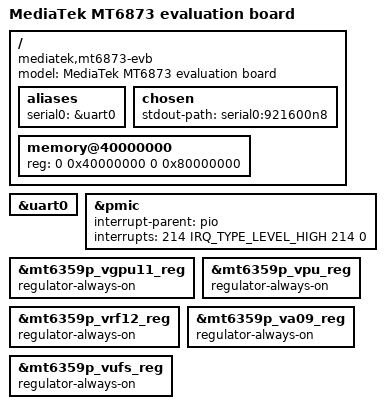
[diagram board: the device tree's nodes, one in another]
// SPDX-License-Identifier: (GPL-2.0 OR MIT)
/*
 * Copyright (C) 2020 MediaTek Inc.
 * Author: Seiya Wang <seiya.wang@mediatek.com>
 */
/dts-v1/;
#include "mt6873.dtsi"
#include "mt6359p.dtsi"

/ {
	model = "MediaTek MT6873 evaluation board";
	compatible = "mediatek,mt6873-evb", "mediatek,mt6873";

	aliases {
		serial0 = &uart0;
	};

	chosen {
		stdout-path = "serial0:921600n8";
	};

	memory@40000000 {
		device_type = "memory";
		reg = <0 0x40000000 0 0x80000000>;
	};
};

&uart0 {
	status = "okay";
};

&pmic {
	interrupt-parent = <&pio>;
	interrupts = <214 IRQ_TYPE_LEVEL_HIGH 214 0>;
};

&mt6359p_vgpu11_reg {
	regulator-always-on;
};

&mt6359p_vpu_reg {
	regulator-always-on;
};

&mt6359p_vrf12_reg {
	regulator-always-on;
};

&mt6359p_va09_reg {
	regulator-always-on;
};

&mt6359p_vufs_reg {
	regulator-always-on;
};
